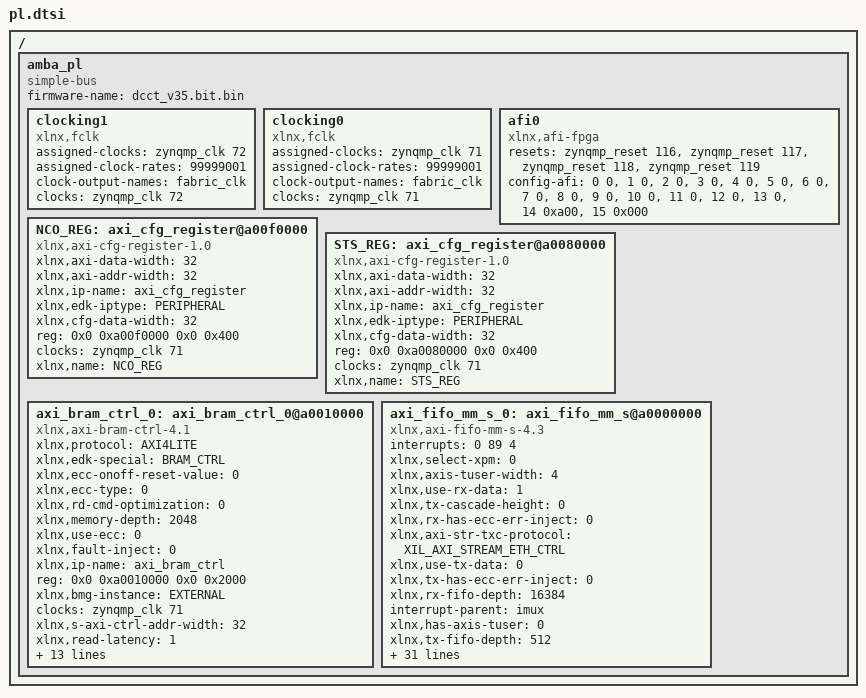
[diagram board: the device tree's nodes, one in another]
/ {
	amba_pl: amba_pl {
		ranges;
		compatible = "simple-bus";
		#address-cells = <2>;
		#size-cells = <2>;
		firmware-name = "dcct_v35.bit.bin";
		clocking1: clocking1 {
			compatible = "xlnx,fclk";
			status = "okay";
			assigned-clocks = <&zynqmp_clk 72>;
			assigned-clock-rates = <99999001>;
			#clock-cells = <0>;
			clock-output-names = "fabric_clk";
			clocks = <&zynqmp_clk 72>;
		};
		clocking0: clocking0 {
			compatible = "xlnx,fclk";
			status = "okay";
			assigned-clocks = <&zynqmp_clk 71>;
			assigned-clock-rates = <99999001>;
			#clock-cells = <0>;
			clock-output-names = "fabric_clk";
			clocks = <&zynqmp_clk 71>;
		};
		afi0: afi0 {
			status = "okay";
			compatible = "xlnx,afi-fpga";
			resets = <&zynqmp_reset 116>, <&zynqmp_reset 117>, <&zynqmp_reset 118>, <&zynqmp_reset 119>;
			config-afi = < 0 0>, <1 0>, <2 0>, <3 0>, <4 0>, <5 0>, <6 0>, <7 0>, <8 0>, <9 0>, <10 0>, <11 0>, <12 0>, <13 0>, <14 0xa00>, <15 0x000>;
		};
		NCO_REG: axi_cfg_register@a00f0000 {
			xlnx,axi-data-width = <32>;
			compatible = "xlnx,axi-cfg-register-1.0";
			status = "okay";
			clock-names = "aclk";
			xlnx,axi-addr-width = <32>;
			xlnx,ip-name = "axi_cfg_register";
			xlnx,edk-iptype = "PERIPHERAL";
			xlnx,cfg-data-width = <32>;
			reg = <0x0 0xa00f0000 0x0 0x400>;
			clocks = <&zynqmp_clk 71>;
			xlnx,name = "NCO_REG";
		};
		STS_REG: axi_cfg_register@a0080000 {
			xlnx,axi-data-width = <32>;
			compatible = "xlnx,axi-cfg-register-1.0";
			status = "okay";
			clock-names = "aclk";
			xlnx,axi-addr-width = <32>;
			xlnx,ip-name = "axi_cfg_register";
			xlnx,edk-iptype = "PERIPHERAL";
			xlnx,cfg-data-width = <32>;
			reg = <0x0 0xa0080000 0x0 0x400>;
			clocks = <&zynqmp_clk 71>;
			xlnx,name = "STS_REG";
		};
		axi_bram_ctrl_0: axi_bram_ctrl_0@a0010000 {
			xlnx,protocol = "AXI4LITE";
			xlnx,edk-special = "BRAM_CTRL";
			compatible = "xlnx,axi-bram-ctrl-4.1" , "xlnx,axi-bram-ctrl";
			xlnx,ecc-onoff-reset-value = <0>;
			xlnx,ecc-type = <0>;
			xlnx,rd-cmd-optimization = <0>;
			xlnx,memory-depth = <2048>;
			xlnx,use-ecc = <0>;
			xlnx,fault-inject = <0>;
			xlnx,ip-name = "axi_bram_ctrl";
			reg = <0x0 0xa0010000 0x0 0x2000>;
			xlnx,bmg-instance = "EXTERNAL";
			clocks = <&zynqmp_clk 71>;
			xlnx,s-axi-ctrl-addr-width = <32>;
			xlnx,read-latency = <1>;
			xlnx,id-width = <0>;
			xlnx,s-axi-supports-narrow-burst = <0>;
			xlnx,supports-narrow-burst = <0>;
			xlnx,single-port-bram = <1>;
			xlnx,ecc = <0>;
			xlnx,edk-iptype = "PERIPHERAL";
			status = "okay";
			clock-names = "s_axi_aclk";
			xlnx,data-width = <32>;
			xlnx,bram-addr-width = <11>;
			xlnx,bram-inst-mode = "EXTERNAL";
			xlnx,s-axi-ctrl-data-width = <32>;
			xlnx,mem-depth = <2048>;
			xlnx,s-axi-id-width = <1>;
			xlnx,name = "axi_bram_ctrl_0";
		};
		axi_fifo_mm_s_0: axi_fifo_mm_s@a0000000 {
			interrupts = < 0 89 4 >;
			xlnx,select-xpm = <0>;
			xlnx,axis-tuser-width = <4>;
			compatible = "xlnx,axi-fifo-mm-s-4.3" , "xlnx,axi-fifo-mm-s";
			xlnx,use-rx-data = <1>;
			xlnx,tx-cascade-height = <0>;
			xlnx,rx-has-ecc-err-inject = <0>;
			xlnx,axi-str-txc-protocol = "XIL_AXI_STREAM_ETH_CTRL";
			xlnx,use-tx-data = <0>;
			xlnx,tx-has-ecc-err-inject = <0>;
			xlnx,rx-fifo-depth = <16384>;
			interrupt-parent = <&imux>;
			xlnx,has-axis-tuser = <0>;
			xlnx,tx-fifo-depth = <512>;
			xlnx,rx-fifo-pe-threshold = <5>;
			xlnx,data-interface-type = <0>;
			xlnx,ip-name = "axi_fifo_mm_s";
			xlnx,use-tx-ctrl = <0>;
			xlnx,rx-fifo-pf-threshold = <507>;
			xlnx,axis-tid-width = <4>;
			reg = <0x0 0xa0000000 0x0 0x2000>;
			clocks = <&zynqmp_clk 71>;
			xlnx,tx-fifo-pe-threshold = <5>;
			xlnx,tx-fifo-pf-threshold = <507>;
			xlnx,s-axi4-data-width = <32>;
			xlnx,has-axis-tstrb = <0>;
			xlnx,axi-str-rxd-protocol = "XIL_AXI_STREAM_ETH_DATA";
			xlnx,use-rx-cut-through = <0>;
			xlnx,axi-str-rxd-tdata-width = <32>;
			xlnx,axis-tdest-width = <4>;
			xlnx,edk-iptype = "PERIPHERAL";
			xlnx,has-axis-tkeep = <0>;
			xlnx,has-axis-tid = <0>;
			xlnx,axi-str-txc-tdata-width = <32>;
			xlnx,axi-str-txd-protocol = "XIL_AXI_STREAM_ETH_DATA";
			xlnx,use-tx-cut-through = <0>;
			xlnx,axi-str-txd-tdata-width = <32>;
			xlnx,rx-enable-ecc = <0>;
			status = "okay";
			clock-names = "s_axi_aclk";
			xlnx,has-axis-tdest = <0>;
			interrupt-names = "interrupt";
			xlnx,tx-enable-ecc = <0>;
			xlnx,s-axi-id-width = <4>;
			xlnx,rx-cascade-height = <0>;
			xlnx,name = "axi_fifo_mm_s_0";
		};
	};
};
